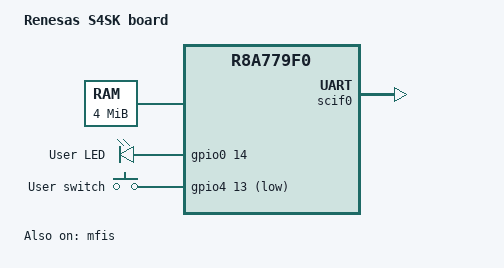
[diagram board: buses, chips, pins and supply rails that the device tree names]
/*
 * Copyright (c) 2022 IoT.bzh
 *
 * SPDX-License-Identifier: Apache-2.0
 *
 */

/dts-v1/;
#include <arm/renesas/gen4/r8a779f0.dtsi>
#include "rcar_s4sk_cr52-pinctrl.dtsi"

/ {
	model = "Renesas S4SK board";
	compatible = "renesas,s4sk-cr52";

	chosen {
		zephyr,sram = &sram0;
		zephyr,console = &scif0; /* Linux is using scif3=hscif0 */
		zephyr,shell-uart = &scif0;
		zephyr,ipc_shm = &sram_shm;
		zephyr,ipc = &mfis;
	};

	/* Size to verify */
	sram_shm: memory@42000000 {
		compatible = "mmio-sram";
		reg = <0x42000000 0x400000>;
	};

	leds {
		compatible = "gpio-leds";
		user_led: led_8 {
			gpios = <&gpio0 14 GPIO_ACTIVE_HIGH>;
			label = "User LED";
		};
	};

	gpio_keys {
		compatible = "gpio-keys";
		/* Supposedly not working (cant use GPIO4 because of pfss) */
		user_button: sw10 {
			gpios = <&gpio4 13 GPIO_ACTIVE_LOW>;
			label = "User switch";
		};
	};

	aliases {
		led0 = &user_led;
		sw0  = &user_button;
	};
};

/* Zephyr console */
&scif0 {
	pinctrl-0 = <&scif0_data_tx_default &scif0_data_rx_default>;
	pinctrl-names = "default";
	status = "okay";
};

/* Linux console */
&scif3 {
	pinctrl-0 = <&scif3_data_tx_default &scif3_data_rx_default>;
	pinctrl-names = "default";
	current-speed = <115200>;
	status = "disabled";
};

&gpio0 {
	status = "okay";
};

&gpio4 {
	status = "okay";
};

&mfis {
       status = "okay";
};
